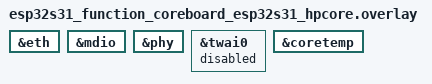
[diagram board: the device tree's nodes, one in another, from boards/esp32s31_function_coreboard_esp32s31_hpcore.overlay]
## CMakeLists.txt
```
# SPDX-License-Identifier: GPL-3.0-or-later

cmake_minimum_required(VERSION 3.20.0)

find_package(Zephyr REQUIRED HINTS $ENV{ZEPHYR_BASE})
project(esp_sdr_ptp_chain)

include(${CMAKE_CURRENT_LIST_DIR}/../../lib/esp_sdr/place.cmake)

target_sources(app PRIVATE src/main.c src/chain.c src/chain_math.c src/stats.c src/shell.c
  src/pps.c)
target_include_directories(app PRIVATE ${CMAKE_CURRENT_LIST_DIR}/../../include)
target_compile_options(app PRIVATE -O2)

# The hook's helpers in IRAM (the hook itself by place.h)
zephyr_linker_sources(RAMFUNC_SECTION ${CMAKE_CURRENT_LIST_DIR}/chain_ram.ld)
```

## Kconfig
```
# SPDX-License-Identifier: GPL-3.0-or-later

mainmenu "PTP chain"

config APP_CHAIN_RING
	int "Exchanges between the receive interrupt and the stats thread (a power of two)"
	range 16 4096
	default 512
	help
	  The thread drains the ring every few ms: it must hold the exchanges of the longest burst
	  (about one per frame) plus that. A full ring drops the exchange and counts it.

config APP_CHAIN_LOG
	int "Exchanges kept for chain dump (a power of two)"
	range 16 8192
	default 4096
	help
	  40 bytes each, in internal RAM.

config APP_CHAIN_PPS_PIN
	int "GPIO that carries the MAC's PPS output (J2 pin 7 is GPIO2)"
	range 0 28
	default 2
	help
	  GPIO0 to GPIO28 (gpio0 has 32 pins, 29 and up are reserved).

config APP_CHAIN_PTP_REF_HZ
	int "Reference clock of the MAC's PTP counter, Hz (PLL_F80M)"
	default 80000000

config APP_CHAIN_PPS
	bool "Route the PPS output to the pin"
	default y

config APP_CHAIN_THREAD_STACK
	int "Stack of the stats thread"
	default 3072

source "Kconfig.zephyr"
```

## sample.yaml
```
sample:
  name: PTP chain
  description: >-
    Clock offset between the DWMAC IEEE 1588 clocks of two ESP32-S31 CoreBoards on a direct
    Ethernet cable, from a ping-pong of raw frames stamped by the MAC hardware
common:
  tags: esp-sdr
  platform_allow:
    - esp32s31_function_coreboard/esp32s31/hpcore
  integration_platforms:
    - esp32s31_function_coreboard/esp32s31/hpcore
tests:
  sample.esp_sdr.ptp_chain:
    build_only: true
```

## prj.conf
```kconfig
# PTP chain: raw frames between two CoreBoards, stamped by the MAC. See README.rst.
CONFIG_ESP_SDR=y
CONFIG_ESP_SDR_PHY_ONLY=y

CONFIG_LOG=y
CONFIG_LOG_MODE_DEFERRED=y
CONFIG_LOG_BUFFER_SIZE=2048
CONFIG_MAIN_STACK_SIZE=2048
CONFIG_PRINTK=y
CONFIG_CBPRINTF_FP_SUPPORT=y
CONFIG_SHELL=y
CONFIG_SHELL_STACK_SIZE=4096
CONFIG_THREAD_NAME=y
# The stats thread fits lines in doubles
CONFIG_FPU_SHARING=y

# Ethernet only: the link comes up with the L2
CONFIG_NETWORKING=y
CONFIG_NET_L2_ETHERNET=y
CONFIG_ETH_DRIVER=y
# INF: the driver logs the PTP clock rate and sub-second increment at boot
CONFIG_ETHERNET_LOG_LEVEL_INF=y
CONFIG_PHY_LOG_LEVEL_WRN=y
CONFIG_MDIO_LOG_LEVEL_WRN=y
CONFIG_MDIO=y
# The stack needs one protocol (net_pkt.c); IPv4 without DHCP or addresses is idle
CONFIG_NET_IPV4=y
CONFIG_NET_IPV6=n
CONFIG_NET_BUF_DATA_SIZE=1536
CONFIG_NET_BUF_ALIGNMENT=64
CONFIG_NET_BUF_RX_COUNT=40
CONFIG_NET_PKT_RX_COUNT=16
CONFIG_NET_PKT_TX_COUNT=4
CONFIG_NET_BUF_TX_COUNT=4
CONFIG_DWMAC_NB_RX_DESCS=16
CONFIG_DWMAC_NB_TX_DESCS=16

# The MAC's hardware clock stamps every frame (a custom EtherType needs ALL). Digital rollover
# (the only mode): the sub-second field is in ns; chain_math.h also converts binary.
CONFIG_PTP_CLOCK=y
CONFIG_PTP_CLOCK_DWC_MAC_RX_TIMESTAMP_ALL=y
CONFIG_PTP_CLOCK_DWC_MAC_FINE_SSINC=y

CONFIG_ETH_DWMAC_RX_FAST=y
CONFIG_ETH_DWMAC_TX_FAST=y
CONFIG_ETH_DWMAC_TX_RAMFUNC=y
# Every frame is stamped: one completion interrupt each
CONFIG_ETH_DWMAC_TX_IRQ_EVERY=1

# Everything of the chain runs on CPU 0: the EMAC interrupt, the hook, the burst timer and the stats
# thread (pinned in src/stats.c). CPU 1 stays idle.
CONFIG_SMP=y
CONFIG_MP_MAX_NUM_CPUS=2
CONFIG_SCHED_CPU_MASK=y
CONFIG_SCHED_CPU_MASK_PIN_ONLY=y
CONFIG_IPI_OPTIMIZE=y

# Burst timer in 100 us ticks (the default interval is 7812 us)
CONFIG_SYS_CLOCK_TICKS_PER_SEC=10000

# Die temperature in the window lines (coretemp, enabled in the board overlay)
CONFIG_SENSOR=y
# Register peeks from the shell (devmem), for the PPS registers
CONFIG_DEVMEM_SHELL=y
```

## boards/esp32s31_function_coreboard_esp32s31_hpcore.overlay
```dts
/*
 * SPDX-License-Identifier: GPL-3.0-or-later
 *
 * The gigabit Ethernet of the ESP32-S31-Function-CoreBoard-1: YT8531 on RGMII (GPIO4-19, MDC 5,
 * MDIO 6, PHY reset 7). TWAI shares GPIO13/14 with TX_CLK and RX_CLK. GPIO2 (J2 pin 7) carries
 * the PPS output (CONFIG_APP_CHAIN_PPS_PIN).
 *
 * Clocks: the YT8531 runs from its own 25 MHz crystal (Y2); the MAC's PTP reference is PLL_F80M
 * (80 MHz), set up in code, not in this devicetree.
 */

&eth {
	status = "okay";
};

&mdio {
	status = "okay";
};

&phy {
	status = "okay";
	/* Gigabit: the 125 MHz reference clock, so let the PHY offer 1000BASE-T. */
	/delete-property/ default-speeds;
};

&twai0 {
	status = "disabled";
};

/* Die temperature for the window lines: the crystal's rate drifts with it */
&coretemp {
	status = "okay";
};
```

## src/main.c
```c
/*
 * SPDX-License-Identifier: GPL-3.0-or-later
 *
 * PTP chain: the offset between two DWMAC clocks from a ping-pong of raw frames. See ../README.rst.
 */
#include <zephyr/kernel.h>
#include <zephyr/logging/log.h>
#include <zephyr/net/ethernet.h>
#include <zephyr/net/net_if.h>

#include "chain.h"

LOG_MODULE_REGISTER(ptp_chain, LOG_LEVEL_INF);

int main(void)
{
	struct net_if *iface = net_if_get_first_by_type(&NET_L2_GET_NAME(ETHERNET));
	int ret;

	if (iface == NULL) {
		LOG_ERR("no Ethernet interface");
		return 0;
	}
	if (!net_if_is_up(iface)) {
		net_if_up(iface);
	}
	ret = chain_init(net_if_get_device(iface), iface);
	if (ret != 0) {
		LOG_ERR("rx hook: %d", ret);
		return 0;
	}
	chain_stats_init();
	if (IS_ENABLED(CONFIG_APP_CHAIN_PPS)) {
		ret = chain_pps_init();
		if (ret != 0) {
			LOG_ERR("pps: %d", ret);
		}
	}
	LOG_INF("ptp_chain ready: 'chain peer <mac>' and 'chain start' on one board");
	return 0;
}
```

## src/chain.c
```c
/*
 * SPDX-License-Identifier: GPL-3.0-or-later
 *
 * The chain of raw frames. The MAC driver calls chain_hook() in the EMAC interrupt for every
 * frame; ours (EtherType 0x88B5, magic) are answered at once from the hook, up to the hop count
 * the frame carries. The seme's burst timer starts each burst. Hook and timer both run on CPU 0
 * and neither nests in the other, so the state needs no lock: a guard flag only counts the case
 * where that assumption breaks.
 *
 * Frame, after the 14 byte Ethernet header, little endian, 40 bytes (padded to 60 on the wire):
 *   0 u16 magic 0x7c1a   2 u8 version 1   3 u8 flags
 *   4 u32 seq            8 u32 reply_to   12 u16 hops left   14 u16 0
 *  16 u32 rx_seq  20 u32 rx_sec  24 u32 rx_subsec   (sender's rx stamp of its last received frame)
 *  28 u32 tx_seq  32 u32 tx_sec  36 u32 tx_subsec   (sender's tx stamp of its previous frame)
 * flags: 0 reply (direct reply to reply_to), 1 sender is seme, 2 rx stamp valid, 3 tx stamp valid.
 * Each node numbers its own frames.
 */
#include <string.h>

#include <zephyr/kernel.h>
#include <zephyr/drivers/ethernet/eth_dwmac_fast.h>
#include <zephyr/net/net_if.h>
#include <zephyr/net_buf.h>
#include <zephyr/sys/atomic.h>
#include <zephyr/sys/util.h>

#include <esp_sdr/esp_sdr_place.h>

#include "chain.h"

#define ETYPE      0x88b5
#define HDR_LEN    14
#define MAGIC      0x7c1a
#define VERSION    1
#define FRAME_LEN  60
#define MAX_HOPS   1024
/* No new burst while a chain frame went in or out less than this ago */
#define QUIET_US   1000

#define P_MAGIC    0
#define P_VER      2
#define P_FLAGS    3
#define P_SEQ      4
#define P_REPLY_TO 8
#define P_HOPS     12
#define P_RX       16   /* seq, sec, subsec */
#define P_TX       28
#define P_END      40

#define F_REPLY    BIT(0)
#define F_SEME     BIT(1)
#define F_RX_OK    BIT(2)
#define F_TX_OK    BIT(3)

#define RING_SLOTS CONFIG_APP_CHAIN_RING
BUILD_ASSERT((RING_SLOTS & (RING_SLOTS - 1)) == 0, "CONFIG_APP_CHAIN_RING: a power of two");
BUILD_ASSERT(CONFIG_NET_BUF_RX_COUNT > CONFIG_DWMAC_NB_RX_DESCS, "receive buffers");

/*
 * Local always-inline accessors: the Zephyr ones (sys_get_le32, atomic_get) are static inline
 * functions that the compiler leaves as calls, to a copy in flash text.
 */
static __always_inline uint32_t get_le32(const uint8_t *p)
{
	return (uint32_t)p[0] | (uint32_t)p[1] << 8 | (uint32_t)p[2] << 16 | (uint32_t)p[3] << 24;
}

static __always_inline uint16_t get_le16(const uint8_t *p)
{
	return (uint16_t)(p[0] | p[1] << 8);
}

static __always_inline uint16_t get_be16(const uint8_t *p)
{
	return (uint16_t)(p[0] << 8 | p[1]);
}

static __always_inline void put_le32(uint32_t v, uint8_t *p)
{
	p[0] = (uint8_t)v;
	p[1] = (uint8_t)(v >> 8);
	p[2] = (uint8_t)(v >> 16);
	p[3] = (uint8_t)(v >> 24);
}

static __always_inline void put_le16(uint16_t v, uint8_t *p)
{
	p[0] = (uint8_t)v;
	p[1] = (uint8_t)(v >> 8);
}

static __always_inline void put_be16(uint16_t v, uint8_t *p)
{
	p[0] = (uint8_t)(v >> 8);
	p[1] = (uint8_t)v;
}

static __always_inline atomic_val_t aget(const atomic_t *a)
{
	return __atomic_load_n(a, __ATOMIC_ACQUIRE);
}

static __always_inline void aset(atomic_t *a, atomic_val_t v)
{
	__atomic_store_n(a, v, __ATOMIC_RELEASE);
}

enum { SLOT_FREE, SLOT_QUEUED, SLOT_DONE };

struct slot {
	uint8_t buf[FRAME_LEN] __aligned(4);
	struct dwmac_tx_stamp stamp;
	atomic_t state;
	uint32_t seq;
	bool harvested;
};

struct chain_counters chain_cnt;
const struct device *chain_eth;

static struct slot slots[CHAIN_TXN];
static struct chain_pair pair;
static uint32_t tx_seq;
static uint8_t own_mac[6];
static const uint8_t bcast_mac[6] = {0xff, 0xff, 0xff, 0xff, 0xff, 0xff};
/* Destination of our frames. peer_state: PEER_NONE, PEER_BUSY (bytes being written), PEER_KNOWN.
 * The bytes are written only in PEER_BUSY and published by the store of PEER_KNOWN.
 */
enum { PEER_NONE, PEER_BUSY, PEER_KNOWN };
static uint8_t peer_mac[6];
static atomic_t peer_state = PEER_NONE;
static atomic_t busy;
static uint32_t last_active_cyc;  /* k_cycle_get_32() at the last chain frame in or out */
static uint32_t quiet_cyc;       /* a burst starts only after this long without a chain frame */
static atomic_t role = CHAIN_IDLE;
static atomic_t rounds = 1;
static atomic_t interval_us = 7812;
static struct k_timer burst_timer;

static struct chain_xchg ring[RING_SLOTS];
static atomic_t ring_head, ring_tail;

static ESP_SDR_CODE(EVENT, chain_slot_done) void chain_slot_done(void *arg)
{
	struct slot *s = arg;

	aset(&s->state, SLOT_DONE);
}

/* Own frames the MAC has stamped since the last call: the stamps go to the pairing records. */
static ESP_SDR_CODE(EVENT, chain_harvest) void chain_harvest(void)
{
	for (unsigned int i = 0; i < CHAIN_TXN; i++) {
		struct slot *s = &slots[i];

		if (aget(&s->state) != SLOT_DONE || s->harvested) {
			continue;
		}
		s->harvested = true;
		if (s->stamp.valid) {
			struct chain_stamp st = {.sec = s->stamp.sec, .subsec = s->stamp.subsec,
						 .valid = true};

			chain_tx_stamp(&pair, s->seq, &st);
		} else {
			chain_cnt.tx_stamp_missing++;
		}
	}
}

static __always_inline void put_stamp(uint8_t *p, uint32_t seq, const struct chain_stamp *st)
{
	put_le32(seq, p);
	put_le32(st->sec, p + 4);
	put_le32(st->subsec, p + 8);
}

/* Queue the next own frame. It carries the rx stamp of the last received frame and the tx stamp of
 * the previous own frame.
 */
static ESP_SDR_CODE(EVENT, chain_send) bool chain_send(bool reply, uint32_t reply_to,
						       uint16_t hops)
{
	struct slot *s = &slots[tx_seq & (CHAIN_TXN - 1U)];
	struct dwmac_tx_frame f;
	struct chain_stamp pt;
	uint8_t *b = s->buf;
	uint8_t *p = b + HDR_LEN;
	uint8_t flags = 0;

	if (aget(&s->state) == SLOT_QUEUED) {
		chain_cnt.tx_busy++;
		return false;
	}
	if (aget(&peer_state) != PEER_KNOWN) {
		chain_cnt.tx_no_peer++;
		return false;
	}
	memset(b, 0, FRAME_LEN);
	memcpy(b, peer_mac, 6);
	if (aget(&peer_state) != PEER_KNOWN) {
		/* the thread changed the peer while we copied */
		chain_cnt.tx_no_peer++;
		return false;
	}
	memcpy(b + 6, own_mac, 6);
	put_be16(ETYPE, b + 12);
	put_le16(MAGIC, p + P_MAGIC);
	p[P_VER] = VERSION;
	if (reply) {
		flags |= F_REPLY;
	}
	if (aget(&role) == CHAIN_SEME) {
		flags |= F_SEME;
	}
	put_le32(tx_seq, p + P_SEQ);
	put_le32(reply_to, p + P_REPLY_TO);
	put_le16(hops, p + P_HOPS);
	if (pair.last.valid && pair.last.rx.valid) {
		put_stamp(p + P_RX, pair.last.seq, &pair.last.rx);
		flags |= F_RX_OK;
	}
	if (chain_tx_get(&pair, tx_seq - 1U, &pt)) {
		put_stamp(p + P_TX, tx_seq - 1U, &pt);
		flags |= F_TX_OK;
	}
	p[P_FLAGS] = flags;

	s->stamp.valid = false;
	s->seq = tx_seq;
	s->harvested = false;
	aset(&s->state, SLOT_QUEUED);
	chain_tx_register(&pair, tx_seq, reply_to, reply);
	f = (struct dwmac_tx_frame){.b1 = b, .l1 = FRAME_LEN, .b2 = NULL, .l2 = 0,
				    .done = chain_slot_done, .arg = s, .stamp = &s->stamp};
	if (dwmac_send_frames(chain_eth, &f, 1) != 1) {
		aset(&s->state, SLOT_FREE);
		chain_cnt.tx_fail++;
		return false;
	}
	tx_seq++;
	chain_cnt.tx_sent++;
	last_active_cyc = k_cycle_get_32();
	return true;
}

static __always_inline void ring_push(const struct chain_xchg *x)
{
	uint32_t h = (uint32_t)aget(&ring_head);

	if (h - (uint32_t)aget(&ring_tail) >= RING_SLOTS) {
		chain_cnt.ring_overflow++;
		return;
	}
	ring[h & (RING_SLOTS - 1U)] = *x;
	aset(&ring_head, (atomic_val_t)(h + 1U));
}

bool chain_ring_pop(struct chain_xchg *x)
{
	uint32_t t = (uint32_t)aget(&ring_tail);

	if (t == (uint32_t)aget(&ring_head)) {
		return false;
	}
	*x = ring[t & (RING_SLOTS - 1U)];
	aset(&ring_tail, (atomic_val_t)(t + 1U));
	return true;
}

static __always_inline void get_stamp(const uint8_t *p, uint32_t *seq, struct chain_stamp *st, bool ok)
{
	*seq = get_le32(p);
	st->sec = get_le32(p + 4);
	st->subsec = get_le32(p + 8);
	st->valid = ok;
}

static ESP_SDR_CODE(EVENT, chain_hook) bool chain_hook(const struct device *dev,
						       const struct dwmac_rx_frame *f, void *user)
{
	const uint8_t *p;
	struct chain_rx_in in;
	struct chain_rx_res res;
	uint8_t flags;
	uint16_t hops;

	ARG_UNUSED(dev);
	ARG_UNUSED(user);
	if (f->len < HDR_LEN + P_END || get_be16(f->data + 12) != ETYPE) {
		return false;
	}
	p = f->data + HDR_LEN;
	if (get_le16(p + P_MAGIC) != MAGIC || p[P_VER] != VERSION ||
	    memcmp(f->data + 6, own_mac, 6) == 0) {
		return false;
	}
	/* for us or broadcast (an older image still sends those) */
	if (memcmp(f->data, own_mac, 6) != 0 && memcmp(f->data, bcast_mac, 6) != 0) {
		return false;
	}
	/* the uke learns the peer from the first valid frame, and keeps it */
	if (atomic_cas(&peer_state, PEER_NONE, PEER_BUSY)) {
		memcpy(peer_mac, f->data + 6, 6);
		aset(&peer_state, PEER_KNOWN);
	}
	if (!atomic_cas(&busy, 0, 1)) {
		chain_cnt.reentry++;
		return false;
	}
	chain_harvest();
	flags = p[P_FLAGS];
	in.seq = get_le32(p + P_SEQ);
	in.is_reply = (flags & F_REPLY) != 0;
	in.reply_to = get_le32(p + P_REPLY_TO);
	get_stamp(p + P_RX, &in.rx_seq, &in.rx, (flags & F_RX_OK) != 0);
	get_stamp(p + P_TX, &in.tx_seq, &in.tx, (flags & F_TX_OK) != 0);
	in.local_rx = (struct chain_stamp){.sec = f->timestamp_sec, .subsec = f->timestamp_subsec,
					   .valid = f->timestamp_valid};
	hops = get_le16(p + P_HOPS);

	if ((flags & F_SEME) != 0) {
		/* two semes: the lower MAC stays */
		if (aget(&role) == CHAIN_SEME && memcmp(f->data + 6, own_mac, 6) < 0) {
			k_timer_stop(&burst_timer);
			aset(&role, CHAIN_UKE);
		} else if (aget(&role) == CHAIN_IDLE) {
			aset(&role, CHAIN_UKE);
		}
	}
	chain_cnt.rx_chain++;
	last_active_cyc = k_cycle_get_32();
	if (!f->timestamp_valid) {
		chain_cnt.rx_nostamp++;
	}
	chain_rx(&pair, &in, &res);
	chain_cnt.rx_lost += res.lost;
	if (res.stale) {
		chain_cnt.rx_stale++;
	} else {
		for (unsigned int i = 0; i < res.n; i++) {
			ring_push(&res.x[i]);
		}
		chain_cnt.exchanges += res.n;
		if (hops > 0) {
			chain_send(true, in.seq, (hops > MAX_HOPS ? MAX_HOPS : hops) - 1U);
		} else {
			chain_cnt.chain_end++;
		}
	}
	aset(&busy, 0);
	net_buf_unref(f->buf);
	return true;
}

/* Tick of the seme: the first frame of a burst. */
static ESP_SDR_CODE(EVENT, chain_burst) void chain_burst(struct k_timer *t)
{
	ARG_UNUSED(t);
	if (!atomic_cas(&busy, 0, 1)) {
		chain_cnt.reentry++;
		return;
	}
	if (k_cycle_get_32() - last_active_cyc < quiet_cyc) {
		chain_cnt.burst_skipped++;
		aset(&busy, 0);
		return;
	}
	chain_harvest();
	if (chain_send(false, 0, 2U * (uint32_t)aget(&rounds) - 1U)) {
		chain_cnt.bursts++;
	}
	aset(&busy, 0);
}

int chain_init(const struct device *eth, struct net_if *iface)
{
	chain_eth = eth;
	memcpy(own_mac, net_if_get_link_addr(iface)->addr, 6);
	chain_pair_init(&pair, CHAIN_DIGITAL);
	quiet_cyc = k_us_to_cyc_ceil32(QUIET_US);
	k_timer_init(&burst_timer, chain_burst, NULL);
	return dwmac_rx_hook_set(eth, chain_hook, NULL, NULL);
}

int chain_start(uint32_t us, uint32_t r)
{
	if (aget(&peer_state) != PEER_KNOWN) {
		return -ENOTCONN;
	}
	if (us != 0) {
		atomic_set(&interval_us, (atomic_val_t)us);
	}
	if (r != 0) {
		atomic_set(&rounds, (atomic_val_t)r);
	}
	atomic_set(&role, CHAIN_SEME);
	k_timer_start(&burst_timer, K_USEC((uint32_t)atomic_get(&interval_us)),
		      K_USEC((uint32_t)atomic_get(&interval_us)));
	return 0;
}

/* Take the peer for writing. The hook (ISR) never waits: it only tries PEER_NONE -> PEER_BUSY. */
static void peer_take(void)
{
	atomic_val_t old;

	do {
		old = aget(&peer_state);
	} while (old == PEER_BUSY || !atomic_cas(&peer_state, old, PEER_BUSY));
}

int chain_peer_set(const uint8_t mac[6])
{
	if (aget(&role) != CHAIN_IDLE) {
		return -EBUSY;
	}
	peer_take();
	memcpy(peer_mac, mac, 6);
	aset(&peer_state, PEER_KNOWN);
	return 0;
}

int chain_peer_clear(void)
{
	if (aget(&role) != CHAIN_IDLE) {
		return -EBUSY;
	}
	peer_take();
	aset(&peer_state, PEER_NONE);
	return 0;
}

bool chain_peer_get(uint8_t mac[6])
{
	if (aget(&peer_state) != PEER_KNOWN) {
		return false;
	}
	memcpy(mac, peer_mac, 6);
	return aget(&peer_state) == PEER_KNOWN;
}

void chain_stop(void)
{
	k_timer_stop(&burst_timer);
	atomic_set(&role, CHAIN_IDLE);
}

enum chain_role chain_role_get(void)
{
	return (enum chain_role)atomic_get(&role);
}

const uint8_t *chain_mac(void)
{
	return own_mac;
}

uint32_t chain_interval_us(void)
{
	return (uint32_t)atomic_get(&interval_us);
}

uint32_t chain_rounds(void)
{
	return (uint32_t)atomic_get(&rounds);
}
```

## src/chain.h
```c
/*
 * SPDX-License-Identifier: GPL-3.0-or-later
 *
 * The chain: hook, sender, burst timer, counters, the exchange ring. See ../README.rst.
 */
#ifndef CHAIN_H_
#define CHAIN_H_

#include <stdbool.h>
#include <stdint.h>

#include <zephyr/device.h>
#include <zephyr/net/net_if.h>

#include "chain_math.h"

#define CHAIN_DIGITAL IS_ENABLED(CONFIG_PTP_CLOCK_DWC_MAC_DIGITAL_ROLLOVER)

enum chain_role {
	CHAIN_IDLE,  /* answers, never starts */
	CHAIN_SEME,  /* starts bursts */
	CHAIN_UKE,   /* has seen a seme */
};

/* Written by the interrupt and the burst timer (CPU 0), read by the thread: only ever counting up */
struct chain_counters {
	uint32_t tx_sent;
	uint32_t tx_busy;           /* slot still queued: ring overflow, frame not sent */
	uint32_t tx_no_peer;        /* no peer MAC known: frame not sent */
	uint32_t tx_fail;           /* the driver took no frame */
	uint32_t tx_stamp_missing;
	uint32_t rx_chain;
	uint32_t rx_nostamp;
	uint32_t rx_stale;
	uint32_t rx_lost;           /* peer frames missing by sequence gap */
	uint32_t exchanges;
	uint32_t ring_overflow;     /* exchange ring full */
	uint32_t reentry;
	uint32_t bursts;
	uint32_t chain_end;         /* bursts that ended here (hop count 0) */
	uint32_t burst_skipped;     /* timer ticks skipped: the previous burst was still running */
	uint32_t rejected;          /* exchanges with an implausible delay (stats thread) */
};

extern struct chain_counters chain_cnt;
extern const struct device *chain_eth;

int chain_init(const struct device *eth, struct net_if *iface);
/** Start bursts. Returns 0, or -ENOTCONN when no peer MAC is known (chain_peer_set() first). */
int chain_start(uint32_t interval_us, uint32_t rounds);
/** Peer MAC (destination of our frames), learned from the first chain frame or set by the user.
 *  Set and clear return -EBUSY unless the role is CHAIN_IDLE.
 */
int chain_peer_set(const uint8_t mac[6]);
int chain_peer_clear(void);
bool chain_peer_get(uint8_t mac[6]);
void chain_stop(void);
enum chain_role chain_role_get(void);
const uint8_t *chain_mac(void);
uint32_t chain_interval_us(void);
uint32_t chain_rounds(void);

/** Next exchange of the ring (thread side). */
bool chain_ring_pop(struct chain_xchg *x);

/* stats.c */
void chain_stats_init(void);
extern atomic_t chain_stat_on;
extern atomic_t chain_servo_on;
uint32_t chain_log_count(void);
bool chain_log_get(uint32_t idx, struct chain_xchg *x);
uint32_t chain_servo_steps(void);
/** Settings of the next 'servo on': period, loop bandwidth in mHz, step clamp in ns. */
void chain_servo_config(uint32_t period_ms, uint32_t bw_mhz, uint32_t clamp_ns);

/* The log entry that marks a servo step: t_ps[0] the step in ps */
#define CHAIN_LOG_STEP 0xffffffffU

/* pps.c */
int chain_pps_init(void);
int chain_pps_set(uint32_t n);
/** Flexible mode: a pulse of width_us every second, rising at a PTP second boundary. */
struct chain_pps_info {
	uint32_t tick_ps;        /* the unit of interval and width */
	uint32_t interval_ticks;
	uint32_t width_ticks;
	uint64_t start_sec;      /* the PTP second the first pulse rises at */
};

int chain_pps_flex(uint32_t width_us, bool ref_clk, struct chain_pps_info *info);
int chain_pps_flex_stop(void);

#endif /* CHAIN_H_ */
```

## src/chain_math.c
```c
/*
 * SPDX-License-Identifier: GPL-3.0-or-later
 *
 * See chain_math.h. chain_rx and the tx records run in the receive interrupt: chain_ram.ld puts
 * them in IRAM.
 */
#include <math.h>
#include <string.h>

#include "chain_math.h"

void chain_pair_init(struct chain_pair *p, bool digital)
{
	memset(p, 0, sizeof(*p));
	p->digital = digital;
}

static struct chain_txrec *tx_find(struct chain_pair *p, uint32_t seq)
{
	struct chain_txrec *r = &p->tx[seq & (CHAIN_TXN - 1U)];

	return (r->used && r->seq == seq) ? r : NULL;
}

void chain_tx_register(struct chain_pair *p, uint32_t seq, uint32_t reply_to, bool is_reply)
{
	struct chain_txrec *r = &p->tx[seq & (CHAIN_TXN - 1U)];

	r->used = true;
	r->seq = seq;
	r->reply_to = reply_to;
	r->is_reply = is_reply;
	r->stamp.valid = false;
}

void chain_tx_stamp(struct chain_pair *p, uint32_t seq, const struct chain_stamp *s)
{
	struct chain_txrec *r = tx_find(p, seq);

	if (r != NULL) {
		r->stamp = *s;
	}
}

bool chain_tx_get(const struct chain_pair *p, uint32_t seq, struct chain_stamp *s)
{
	const struct chain_txrec *r = &p->tx[seq & (CHAIN_TXN - 1U)];

	if (!r->used || r->seq != seq || !r->stamp.valid) {
		return false;
	}
	*s = r->stamp;
	return true;
}

static void emit(const struct chain_pair *p, struct chain_rx_res *res, uint32_t seq,
		 const struct chain_stamp *t1, const struct chain_stamp *t2,
		 const struct chain_stamp *t3, const struct chain_stamp *t4)
{
	struct chain_xchg *x = &res->x[res->n++];

	x->seq = seq;
	x->base_sec = t1->sec;
	x->t_ps[0] = chain_stamp_rel_ps(t1, t1->sec, p->digital);
	x->t_ps[1] = chain_stamp_rel_ps(t2, t1->sec, p->digital);
	x->t_ps[2] = chain_stamp_rel_ps(t3, t1->sec, p->digital);
	x->t_ps[3] = chain_stamp_rel_ps(t4, t1->sec, p->digital);
}

void chain_rx(struct chain_pair *p, const struct chain_rx_in *in, struct chain_rx_res *res)
{
	struct chain_rxrec *l = &p->last;
	struct chain_txrec *m;

	res->n = 0;
	res->stale = false;
	res->lost = 0;

	if (l->valid) {
		int32_t d = (int32_t)(in->seq - l->seq);

		if (d <= 0 && d >= -CHAIN_STALE_WIN) {
			res->stale = true;
			return;
		}
		if (d > 0 && (uint32_t)d < CHAIN_RESYNC) {
			res->lost = (uint32_t)d - 1U;
		}
	}

	/*
	 * Pair started by us: own m, peer's direct reply l (carries its rx of m), and now the frame
	 * after l carries the peer's tx stamp of l.
	 */
	if (l->valid && l->is_reply && l->rx.valid && l->crx.valid && in->tx.valid &&
	    in->tx_seq == l->seq && l->crx_seq == l->reply_to) {
		m = tx_find(p, l->reply_to);
		if (m != NULL && m->stamp.valid) {
			emit(p, res, m->seq, &m->stamp, &l->crx, &in->tx, &l->rx);
		}
	}

	/*
	 * Pair started by the peer: its frame l (rx here) and our direct reply m. Any later frame of
	 * the peer (a reply to m or the first frame of the next burst) is the carrier: it holds the
	 * peer's tx stamp of l (tx_seq) and its rx stamp of m (rx_seq).
	 */
	if (l->valid && l->rx.valid && in->tx.valid && in->rx.valid && in->tx_seq == l->seq) {
		m = tx_find(p, in->rx_seq);
		if (m != NULL && m->is_reply && m->reply_to == l->seq && m->stamp.valid) {
			emit(p, res, l->seq, &m->stamp, &in->rx, &in->tx, &l->rx);
		}
	}

	l->valid = true;
	l->seq = in->seq;
	l->is_reply = in->is_reply;
	l->reply_to = in->reply_to;
	l->rx = in->local_rx;
	l->crx_seq = in->rx_seq;
	l->crx = in->rx;
}

void chain_fit_reset(struct chain_fit *f)
{
	memset(f, 0, sizeof(*f));
}

void chain_fit_add(struct chain_fit *f, int64_t x_ps, int64_t y_ps)
{
	double dx_ps, dy_ps;

	if (f->n == 0) {
		f->x0_ps = (double)x_ps;
		f->y0_ps = (double)y_ps;
	}
	dx_ps = (double)x_ps - f->x0_ps;
	dy_ps = (double)y_ps - f->y0_ps;
	f->n++;
	f->sx_ps += dx_ps;
	f->sy_ps += dy_ps;
	f->sxx_ps2 += dx_ps * dx_ps;
	f->sxy_ps2 += dx_ps * dy_ps;
	f->syy_ps2 += dy_ps * dy_ps;
}

int chain_fit_end(const struct chain_fit *f, struct chain_fit_res *r)
{
	double n = (double)f->n;
	double cxx_ps2, cxy_ps2, cyy_ps2, slope, var;

	memset(r, 0, sizeof(*r));
	r->n = f->n;
	if (f->n == 0) {
		return -1;
	}
	r->x_mean_ps = f->x0_ps + f->sx_ps / n;
	r->y_mean_ps = f->y0_ps + f->sy_ps / n;
	cxx_ps2 = f->sxx_ps2 - f->sx_ps * f->sx_ps / n;
	cxy_ps2 = f->sxy_ps2 - f->sx_ps * f->sy_ps / n;
	cyy_ps2 = f->syy_ps2 - f->sy_ps * f->sy_ps / n;
	if (f->n < 2 || cxx_ps2 <= 0.0) {
		r->rms_ps = sqrt(cyy_ps2 > 0.0 ? cyy_ps2 / n : 0.0);
		return -1;
	}
	slope = cxy_ps2 / cxx_ps2;
	var = (cyy_ps2 - slope * cxy_ps2) / n;
	r->rate_ppb = slope * 1e9;
	r->rms_ps = sqrt(var > 0.0 ? var : 0.0);
	return 0;
}

void chain_servo_init(struct chain_servo *s, double period_s, double bw_hz, double clamp_ps)
{
	double wn = CHAIN_TAU * bw_hz;

	memset(s, 0, sizeof(*s));
	s->kp = 2.0 * wn / 1e3;
	s->ki = wn * wn / 1e3;
	s->period_s = period_s;
	s->clamp_ps = clamp_ps;
}

double chain_servo_update(struct chain_servo *s, double offset_ps, int64_t *step_ps)
{
	double integ, out;

	*step_ps = 0;
	if (fabs(offset_ps) > s->clamp_ps) {
		*step_ps = (int64_t)llround(offset_ps);
		s->steps++;
		return s->rate_ppb;
	}
	integ = s->integ_ppb + s->ki * offset_ps * s->period_s;
	out = s->kp * offset_ps + integ;
	/* the output limit also stops the integrator (no windup against it) */
	if (out > CHAIN_SERVO_MAX_PPB) {
		integ -= out - CHAIN_SERVO_MAX_PPB;
		out = CHAIN_SERVO_MAX_PPB;
	} else if (out < -CHAIN_SERVO_MAX_PPB) {
		integ -= out + CHAIN_SERVO_MAX_PPB;
		out = -CHAIN_SERVO_MAX_PPB;
	}
	s->integ_ppb = integ;
	s->rate_ppb = out;
	return out;
}
```

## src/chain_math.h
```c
/*
 * SPDX-License-Identifier: GPL-3.0-or-later
 *
 * The arithmetic of the PTP chain: MAC stamps to picoseconds, the pairing of frames into
 * exchanges, offset and delay of an exchange, the least-squares line. Only stdint, stdbool and
 * math: the host unit test (tests/unit/ptp_chain) compiles chain_math.c as it is.
 *
 * Time is int64 picoseconds. A stamp is (sec, subsec) from the MAC; seconds are taken relative to
 * a base second (the one of t1), so a clock that is off by up to CHAIN_SEC_LIM seconds (97 days)
 * still fits; beyond that the difference saturates.
 */
#ifndef CHAIN_MATH_H_
#define CHAIN_MATH_H_

#include <stdbool.h>
#include <stdint.h>

/* The hot helpers are part of the caller: it runs from IRAM */
#define CHAIN_INLINE static inline __attribute__((always_inline))

#define CHAIN_PS_PER_SEC 1000000000000LL
#define CHAIN_SEC_LIM    8000000

/* 1e12 = 2^12 * 5^12: a binary sub-second (units of 2^-31 s) is subsec * 5^12 / 2^19 ps, exact */
#define CHAIN_BIN_MUL    244140625ULL
#define CHAIN_BIN_SHIFT  19
#define CHAIN_BIN_MASK   0x7fffffffU
#define CHAIN_NS_PER_SEC 1000000000U

/* Own frames kept for pairing (a power of two); the chain needs two */
#define CHAIN_TXN        8U
/* A frame this far behind the last one is stale (reordered or repeated), further is a peer restart */
#define CHAIN_STALE_WIN  64
/* A jump of this many frames or more is a restart of the peer, not a loss */
#define CHAIN_RESYNC     65536U

struct chain_stamp {
	uint32_t sec;
	uint32_t subsec;
	bool valid;
};

/** a is older than b, u32 sequence numbers with wrap */
CHAIN_INLINE bool chain_seq_lt(uint32_t a, uint32_t b)
{
	return (int32_t)(a - b) < 0;
}

/** Sub-second field to ps: digital rollover counts ns, binary counts 2^-31 s. */
CHAIN_INLINE int64_t chain_subsec_to_ps(uint32_t subsec, bool digital)
{
	if (digital) {
		if (subsec >= CHAIN_NS_PER_SEC) {
			subsec = CHAIN_NS_PER_SEC - 1U;
		}
		return (int64_t)subsec * 1000;
	}
	return (int64_t)(((uint64_t)(subsec & CHAIN_BIN_MASK) * CHAIN_BIN_MUL) >> CHAIN_BIN_SHIFT);
}

/** Stamp in ps counted from the start of second base_sec (negative before it; seconds saturate). */
CHAIN_INLINE int64_t chain_stamp_rel_ps(const struct chain_stamp *s, uint32_t base_sec,
					 bool digital)
{
	int32_t ds = (int32_t)(s->sec - base_sec);

	if (ds > CHAIN_SEC_LIM) {
		ds = CHAIN_SEC_LIM;
	} else if (ds < -CHAIN_SEC_LIM) {
		ds = -CHAIN_SEC_LIM;
	}
	return (int64_t)ds * CHAIN_PS_PER_SEC + chain_subsec_to_ps(s->subsec, digital);
}

/*
 * An exchange as seen from the local node X, the peer being Y:
 * t1 = X tx, t2 = Y rx, t3 = Y tx, t4 = X rx (all relative to base_sec).
 * A pair started by X is natural order. A pair started by Y (Y tx p, X rx p, X tx s, Y rx s) is
 * stored as t1 = X tx s, t2 = Y rx s, t3 = Y tx p, t4 = X rx p: the same formulas give Y minus X.
 */
struct chain_xchg {
	uint32_t seq;      /* first frame of the pair */
	uint32_t base_sec;
	int64_t t_ps[4];
};

/** Y minus X, ps (floor of half ps) */
CHAIN_INLINE int64_t chain_xchg_offset_ps(const struct chain_xchg *x)
{
	return ((x->t_ps[1] - x->t_ps[0]) - (x->t_ps[3] - x->t_ps[2])) >> 1;
}

/** Mean of the two one-way delays, ps */
CHAIN_INLINE int64_t chain_xchg_delay_ps(const struct chain_xchg *x)
{
	return ((x->t_ps[1] - x->t_ps[0]) + (x->t_ps[3] - x->t_ps[2])) >> 1;
}

/* Pairing */

struct chain_txrec {
	bool used;
	bool is_reply;
	uint32_t seq;
	uint32_t reply_to;
	struct chain_stamp stamp;
};

struct chain_rxrec {
	bool valid;
	bool is_reply;
	uint32_t seq;
	uint32_t reply_to;
	struct chain_stamp rx;  /* local rx stamp of this frame */
	uint32_t crx_seq;       /* the stamp the peer carried: its rx of frame crx_seq */
	struct chain_stamp crx;
};

struct chain_pair {
	bool digital;
	struct chain_txrec tx[CHAIN_TXN];
	struct chain_rxrec last;
};

/** A received chain frame: its header, the stamps it carries, and the local rx stamp. */
struct chain_rx_in {
	uint32_t seq;
	bool is_reply;
	uint32_t reply_to;
	uint32_t rx_seq;
	struct chain_stamp rx;  /* peer's rx stamp of its last received frame rx_seq */
	uint32_t tx_seq;
	struct chain_stamp tx;  /* peer's tx stamp of its previous frame tx_seq */
	struct chain_stamp local_rx;
};

struct chain_rx_res {
	uint8_t n;              /* exchanges completed by this frame (0 to 2) */
	bool stale;             /* repeated or reordered: ignored */
	uint32_t lost;          /* peer frames missing since the last one */
	struct chain_xchg x[2];
};

void chain_pair_init(struct chain_pair *p, bool digital);
/** Own frame seq is queued (reply_to meaningful if is_reply). */
void chain_tx_register(struct chain_pair *p, uint32_t seq, uint32_t reply_to, bool is_reply);
/** The MAC's tx stamp of own frame seq arrived. */
void chain_tx_stamp(struct chain_pair *p, uint32_t seq, const struct chain_stamp *s);
/** The tx stamp of own frame seq, false if unknown or the stamp is invalid. */
bool chain_tx_get(const struct chain_pair *p, uint32_t seq, struct chain_stamp *s);
/** Process a received frame: completes the exchanges it allows, then becomes the last frame. */
void chain_rx(struct chain_pair *p, const struct chain_rx_in *in, struct chain_rx_res *res);

/* Least squares line y = y_mean + slope (x - x_mean), accumulated sample by sample */

struct chain_fit {
	uint32_t n;
	double x0_ps, y0_ps;                 /* first sample: the sums are about it */
	double sx_ps, sy_ps;
	double sxx_ps2, sxy_ps2, syy_ps2;
};

struct chain_fit_res {
	uint32_t n;
	double x_mean_ps;
	double y_mean_ps;    /* the line at x_mean_ps */
	double rate_ppb;     /* slope of y over x */
	double rms_ps;       /* residual */
};

void chain_fit_reset(struct chain_fit *f);
void chain_fit_add(struct chain_fit *f, int64_t x_ps, int64_t y_ps);
/** 0 if the line is defined; -1 (means filled, rate 0) for fewer than 2 points or equal x. */
int chain_fit_end(const struct chain_fit *f, struct chain_fit_res *r);

/*
 * Rate-only PI servo of the uke. Input: offset of the seme (peer minus local, ps), the mean over
 * one update period. Output: the absolute rate of the local clock in ppb of nominal (ratio
 * 1 + rate_ppb * 1e-9). Positive offset means the local clock is behind: speed up.
 *
 * Plant: offset' = -1e3 (rate_ppb + clock error) ps/s. With rate = kp e + integ and
 * integ' = ki e this is a second order loop of natural frequency wn = TAU bw_hz,
 * critically damped: kp = 2 wn / 1e3, ki = wn^2 / 1e3 (ppb per ps, ppb per ps and s).
 * A step (|offset| above the clamp) is returned to the caller and the update leaves rate and
 * integrator alone: the learned rate survives a step and nothing winds up.
 */
#define CHAIN_TAU 6.283185307179586
#define CHAIN_SERVO_MAX_PPB 100000.0

struct chain_servo {
	double kp;          /* ppb per ps */
	double ki;          /* ppb per ps and s */
	double period_s;
	double clamp_ps;    /* above this the clock is stepped */
	double integ_ppb;
	double rate_ppb;    /* last output */
	uint32_t steps;
};

void chain_servo_init(struct chain_servo *s, double period_s, double bw_hz, double clamp_ps);
/** One update; *step_ps is the step to apply to the local clock (0: none). Returns rate_ppb. */
double chain_servo_update(struct chain_servo *s, double offset_ps, int64_t *step_ps);

#endif /* CHAIN_MATH_H_ */
```

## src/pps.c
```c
/*
 * SPDX-License-Identifier: GPL-3.0-or-later
 *
 * The MAC's PPS0 output on a GPIO: the pad is made an output by the GPIO driver, then the GPIO
 * matrix connects the EMAC PPS signal to it. The pulse shape is unverified (README).
 */
#include <zephyr/device.h>
#include <zephyr/devicetree.h>
#include <zephyr/drivers/gpio.h>
#include <zephyr/drivers/ptp_clock.h>
#include <zephyr/net/ptp_time.h>
#include <zephyr/sys/util.h>

#include <esp_rom_gpio.h>
#include <soc/emac_ptp_struct.h>
#include <soc/gpio_sig_map.h>

#include "chain.h"

int chain_pps_init(void)
{
	const struct device *gpio = DEVICE_DT_GET(DT_NODELABEL(gpio0));
	int ret;

	if (!device_is_ready(gpio)) {
		return -ENODEV;
	}
	ret = gpio_pin_configure(gpio, CONFIG_APP_CHAIN_PPS_PIN, GPIO_OUTPUT_INACTIVE);
	if (ret != 0) {
		return ret;
	}
	esp_rom_gpio_connect_out_signal(CONFIG_APP_CHAIN_PPS_PIN, EMAC_PTP_PPS_PAD_OUT_IDX, false, false);
	return 0;
}

/* PPS control register (EMAC_PTP + 0x2c, the DWMAC 3.7 PPSCTRL at 0x72c) */
#define PPS_CTRL_PPSEN0        BIT(4)      /* flexible mode: PPSCMD0 is a command */
#define PPS_CTRL_TRGT_SHIFT    5           /* TRGTMODSEL0, 2 bits */
#define PPS_TRGT_PPS_ONLY      3U          /* target time starts or stops the output, no interrupt */
#define PPS_CMD_START_TRAIN    2U
#define PPS_CMD_STOP_NOW       5U
/* The registers are 31 bits of nanoseconds and a busy flag */
#define PPS_WAIT_LOOPS         100000

/** Fixed mode: PPS0 control field (4 bits), PPSEN0 off. */
int chain_pps_set(uint32_t n)
{
	if (n > 15U) {
		return -EINVAL;
	}
	EMAC_PTP.pps_ctrl.val = n;
	return 0;
}

static int target_wait(volatile uint32_t *nsec_reg)
{
	for (int i = 0; i < PPS_WAIT_LOOPS; i++) {
		if ((*nsec_reg & BIT(31)) == 0U) {
			return 0;
		}
	}
	return -ETIMEDOUT;
}

/*
 * Is flexible mode there: select it (PPSEN0, stop command) and write a pattern to the PPS0
 * interval register. The S31 keeps only the fixed-mode field (pps_ctrl reads back 0x5) and the
 * interval reads 0: then the old control value is written back, so a fixed-mode output runs on.
 */
static int flex_probe(void)
{
	uint32_t ctrl_old = EMAC_PTP.pps_ctrl.val;

	EMAC_PTP.pps_ctrl.val = PPS_CTRL_PPSEN0 | (PPS_TRGT_PPS_ONLY << PPS_CTRL_TRGT_SHIFT) |
				PPS_CMD_STOP_NOW;
	EMAC_PTP.pps0_interval.val = 0x5a5aa5a5U;
	if ((EMAC_PTP.pps_ctrl.val & PPS_CTRL_PPSEN0) == 0U ||
	    EMAC_PTP.pps0_interval.val != 0x5a5aa5a5U) {
		EMAC_PTP.pps_ctrl.val = ctrl_old;
		return -ENODEV;
	}
	return 0;
}

/*
 * Flexible mode: a pulse train, interval 1 s, width width_us, first rising edge at the PTP second
 * two seconds on (the next full second plus one, so the registers are in before it). Interval and
 * width are programmed as ticks - 1. A tick is the sub-second increment of the PTP clock
 * (SSIR: 13 ns with FINE_SSINC at 80 MHz), or with ref_clk one cycle of the PTP reference clock
 * (12.5 ns): which unit the MAC counts in is unverified, read it off the scope.
 */
int chain_pps_flex(uint32_t width_us, bool ref_clk, struct chain_pps_info *info)
{
	const struct device *clk = DEVICE_DT_GET(DT_NODELABEL(ptp_clock));
	struct net_ptp_time t;
	uint64_t tick_ps;
	int ret;

	if (width_us == 0U) {
		width_us = 1000U;
	}
	if (ref_clk) {
		tick_ps = (uint64_t)CHAIN_PS_PER_SEC / CONFIG_APP_CHAIN_PTP_REF_HZ;
	} else {
		tick_ps = (uint64_t)chain_subsec_to_ps(EMAC_PTP.sub_sec_incre.sub_second_incre_value,
						      CHAIN_DIGITAL);
	}
	if (tick_ps == 0U) {
		return -EINVAL;
	}
	info->tick_ps = (uint32_t)tick_ps;
	info->interval_ticks = (uint32_t)(((uint64_t)CHAIN_PS_PER_SEC + tick_ps / 2U) / tick_ps);
	info->width_ticks = (uint32_t)(((uint64_t)width_us * 1000000U + tick_ps / 2U) / tick_ps);
	if (info->width_ticks == 0U || info->width_ticks >= info->interval_ticks) {
		return -EINVAL;
	}
	ret = flex_probe();
	if (ret != 0) {
		return ret;
	}
	ret = ptp_clock_get(clk, &t);
	if (ret != 0) {
		return ret;
	}
	info->start_sec = t.second + 2U;

	/* stop what runs, select flexible mode, program, then the start command */
	EMAC_PTP.pps_ctrl.val = PPS_CTRL_PPSEN0 | (PPS_TRGT_PPS_ONLY << PPS_CTRL_TRGT_SHIFT) |
				PPS_CMD_STOP_NOW;
	EMAC_PTP.pps_ctrl.val = PPS_CTRL_PPSEN0 | (PPS_TRGT_PPS_ONLY << PPS_CTRL_TRGT_SHIFT);
	EMAC_PTP.pps0_interval.val = info->interval_ticks - 1U;
	EMAC_PTP.pps0_width.val = info->width_ticks - 1U;
	EMAC_PTP.tgt_seconds.val = (uint32_t)info->start_sec;
	ret = target_wait(&EMAC_PTP.tgt_nanosec.val);
	if (ret != 0) {
		return ret;
	}
	EMAC_PTP.tgt_nanosec.val = 0U;
	ret = target_wait(&EMAC_PTP.tgt_nanosec.val);
	if (ret != 0) {
		return ret;
	}
	EMAC_PTP.pps_ctrl.val = PPS_CTRL_PPSEN0 | (PPS_TRGT_PPS_ONLY << PPS_CTRL_TRGT_SHIFT) |
				PPS_CMD_START_TRAIN;
	return 0;
}

/* Stops a flexible train; -ENODEV and nothing changed without flexible mode (the S31) */
int chain_pps_flex_stop(void)
{
	uint32_t ctrl_old = EMAC_PTP.pps_ctrl.val;

	EMAC_PTP.pps_ctrl.val = PPS_CTRL_PPSEN0 | (PPS_TRGT_PPS_ONLY << PPS_CTRL_TRGT_SHIFT) |
				PPS_CMD_STOP_NOW;
	if ((EMAC_PTP.pps_ctrl.val & PPS_CTRL_PPSEN0) == 0U) {
		EMAC_PTP.pps_ctrl.val = ctrl_old;
		return -ENODEV;
	}
	return 0;
}
```

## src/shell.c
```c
/*
 * SPDX-License-Identifier: GPL-3.0-or-later
 *
 * Shell: chain start|stop|peer|stat|dump|info|servo|pps.
 */
#include <ctype.h>
#include <stdlib.h>

#include <zephyr/drivers/ethernet/eth_dwmac_fast.h>
#include <zephyr/device.h>
#include <zephyr/drivers/ptp_clock.h>
#include <zephyr/net/phy.h>
#include <zephyr/net/ptp_time.h>
#include <zephyr/shell/shell.h>

#include "chain.h"

static const char *const role_name[] = {"idle", "seme", "uke"};

static int cmd_start(const struct shell *sh, size_t argc, char **argv)
{
	uint32_t us = argc > 1 ? strtoul(argv[1], NULL, 0) : 0;
	uint32_t rounds = argc > 2 ? strtoul(argv[2], NULL, 0) : 0;

	if (us != 0 && us < 100) {
		shell_error(sh, "interval_us at least 100");
		return -EINVAL;
	}
	if (rounds > 100) {
		shell_error(sh, "rounds_per_burst at most 100");
		return -EINVAL;
	}
	if (chain_start(us, rounds) != 0) {
		shell_error(sh, "no peer: chain peer <mac> first (the other board's MAC from chain info)");
		return -ENOTCONN;
	}
	shell_print(sh, "seme: interval %u us, %u rounds per burst", chain_interval_us(),
		    chain_rounds());
	return 0;
}

/* Parse aa:bb:cc:dd:ee:ff, exactly 6 bytes of 2 hex digits. */
static bool parse_mac(const char *s, uint8_t mac[6])
{
	for (int i = 0; i < 6; i++) {
		int hi, lo;

		if (!isxdigit((unsigned char)s[0]) || !isxdigit((unsigned char)s[1])) {
			return false;
		}
		hi = isdigit((unsigned char)s[0]) ? s[0] - '0' : (tolower((unsigned char)s[0]) - 'a' + 10);
		lo = isdigit((unsigned char)s[1]) ? s[1] - '0' : (tolower((unsigned char)s[1]) - 'a' + 10);
		mac[i] = (uint8_t)(hi << 4 | lo);
		s += 2;
		if (i < 5 && *s++ != ':') {
			return false;
		}
	}
	return *s == '\0';
}

/* peer [<mac> | clear] */
static int cmd_peer(const struct shell *sh, size_t argc, char **argv)
{
	uint8_t m[6];
	int ret;

	if (argc == 1) {
		if (chain_peer_get(m)) {
			shell_print(sh, "peer %02x:%02x:%02x:%02x:%02x:%02x", m[0], m[1], m[2], m[3],
				    m[4], m[5]);
		} else {
			shell_print(sh, "peer none");
		}
		return 0;
	}
	if (strcmp(argv[1], "clear") == 0) {
		ret = chain_peer_clear();
	} else if (parse_mac(argv[1], m)) {
		ret = chain_peer_set(m);
	} else {
		shell_error(sh, "peer <aa:bb:cc:dd:ee:ff> | clear");
		return -EINVAL;
	}
	if (ret != 0) {
		shell_error(sh, "chain is running: chain stop first");
		return ret;
	}
	return 0;
}

static int cmd_stop(const struct shell *sh, size_t argc, char **argv)
{
	chain_stop();
	shell_print(sh, "stopped (still answers)");
	return 0;
}

static int onoff(const struct shell *sh, const char *s, atomic_t *flag, const char *name)
{
	if (strcmp(s, "on") == 0) {
		atomic_set(flag, 1);
	} else if (strcmp(s, "off") == 0) {
		atomic_set(flag, 0);
	} else {
		shell_error(sh, "on or off");
		return -EINVAL;
	}
	shell_print(sh, "%s %s", name, s);
	return 0;
}

static int cmd_stat(const struct shell *sh, size_t argc, char **argv)
{
	return onoff(sh, argv[1], &chain_stat_on, "stat");
}

/* servo on [period_ms] [bw_hz] [clamp_ns] | off */
static int cmd_servo(const struct shell *sh, size_t argc, char **argv)
{
	if (strcmp(argv[1], "on") == 0) {
		uint32_t period_ms = argc > 2 ? strtoul(argv[2], NULL, 0) : 50;
		double bw_hz = argc > 3 ? strtod(argv[3], NULL) : 2.0;
		uint32_t clamp_ns = argc > 4 ? strtoul(argv[4], NULL, 0) : 500;

		if (period_ms < 10 || period_ms > 1000 || bw_hz < 0.01 || bw_hz > 10.0 ||
		    clamp_ns == 0) {
			shell_error(sh, "period_ms 10..1000, bw_hz 0.01..10, clamp_ns > 0");
			return -EINVAL;
		}
		chain_servo_config(period_ms, (uint32_t)(bw_hz * 1000.0 + 0.5), clamp_ns);
		atomic_set(&chain_servo_on, 1);
		shell_print(sh, "servo on (uke only): period %u ms, bandwidth %.3f Hz, clamp %u ns",
			    period_ms, bw_hz, clamp_ns);
		return 0;
	}
	return onoff(sh, argv[1], &chain_servo_on, "servo");
}

/* seq,base_sec,t1_ps,t2_ps,t3_ps,t4_ps; a servo step as a # line */
static int cmd_dump(const struct shell *sh, size_t argc, char **argv)
{
	uint32_t end = chain_log_count();
	uint32_t n = argc > 1 ? strtoul(argv[1], NULL, 0) : CONFIG_APP_CHAIN_LOG;
	uint32_t i;

	if (n > CONFIG_APP_CHAIN_LOG) {
		n = CONFIG_APP_CHAIN_LOG;
	}
	if (n > end) {
		n = end;
	}
	shell_print(sh, "# seq,base_sec,t1_ps,t2_ps,t3_ps,t4_ps (t1,t4 local, t2,t3 peer; offset = peer - local)");
	for (i = end - n; i != end; i++) {
		struct chain_xchg x;

		if (!chain_log_get(i, &x)) {
			shell_warn(sh, "# log overwritten while printing");
			break;
		}
		if (x.seq == CHAIN_LOG_STEP) {
			shell_print(sh, "# servo step %lld ps", (long long)x.t_ps[0]);
			continue;
		}
		shell_print(sh, "%u,%u,%lld,%lld,%lld,%lld", x.seq, x.base_sec,
			    (long long)x.t_ps[0], (long long)x.t_ps[1], (long long)x.t_ps[2],
			    (long long)x.t_ps[3]);
	}
	return 0;
}

static int cmd_info(const struct shell *sh, size_t argc, char **argv)
{
	const struct device *clk = DEVICE_DT_GET(DT_NODELABEL(ptp_clock));
	const struct device *phy = DEVICE_DT_GET(DT_NODELABEL(phy));
	const uint8_t *m = chain_mac();
	uint8_t pm[6];
	struct net_ptp_time t;
	struct phy_link_state ls;
	struct dwmac_rx_stats rs;
	int ret;

	shell_print(sh, "mac %02x:%02x:%02x:%02x:%02x:%02x role %s interval %u us rounds %u", m[0],
		    m[1], m[2], m[3], m[4], m[5], role_name[chain_role_get()], chain_interval_us(),
		    chain_rounds());
	if (chain_peer_get(pm)) {
		shell_print(sh, "peer %02x:%02x:%02x:%02x:%02x:%02x", pm[0], pm[1], pm[2], pm[3],
			    pm[4], pm[5]);
	} else {
		shell_print(sh, "peer none");
	}
	shell_print(sh, "ptp subsec: %s, fine ssinc %s", CHAIN_DIGITAL ? "digital (ns)" : "binary (2^-31 s)",
		    IS_ENABLED(CONFIG_PTP_CLOCK_DWC_MAC_FINE_SSINC) ? "yes" : "no");
	ret = ptp_clock_get(clk, &t);
	if (ret == 0) {
		shell_print(sh, "ptp time %llu.%09u s", (unsigned long long)t.second, t.nanosecond);
	}
	ret = phy_get_link_state(phy, &ls);
	if (ret == 0) {
		shell_print(sh, "link %s speed %s", ls.is_up ? "up" : "down",
			    PHY_LINK_IS_SPEED_1000M(ls.speed) ? "1000M" :
			    PHY_LINK_IS_SPEED_100M(ls.speed) ? "100M" :
			    PHY_LINK_IS_SPEED_10M(ls.speed) ? "10M" : "?");
	}
	dwmac_rx_stats_get(chain_eth, &rs);
	shell_print(sh, "mac rx: offered %u claimed %u missed %u fifo_ovf %u starved %u", rs.offered,
		    rs.claimed, rs.missed, rs.fifo_overflow, rs.starved);
	shell_print(sh, "tx sent %u busy %u no_peer %u fail %u stamp_missing %u", chain_cnt.tx_sent,
		    chain_cnt.tx_busy, chain_cnt.tx_no_peer, chain_cnt.tx_fail,
		    chain_cnt.tx_stamp_missing);
	shell_print(sh, "rx chain %u nostamp %u stale %u lost %u", chain_cnt.rx_chain,
		    chain_cnt.rx_nostamp, chain_cnt.rx_stale, chain_cnt.rx_lost);
	shell_print(sh, "exchanges %u rejected %u ring_overflow %u reentry %u bursts %u skipped %u chain_end %u",
		    chain_cnt.exchanges, chain_cnt.rejected, chain_cnt.ring_overflow,
		    chain_cnt.reentry, chain_cnt.bursts, chain_cnt.burst_skipped, chain_cnt.chain_end);
	shell_print(sh, "stat %s servo %s (steps %u) log %u", atomic_get(&chain_stat_on) ? "on" : "off",
		    atomic_get(&chain_servo_on) ? "on" : "off", chain_servo_steps(),
		    chain_log_count());
	return 0;
}

/* pps <n> | pps flex [width_us] [clk] | pps stop */
static int cmd_pps(const struct shell *sh, size_t argc, char **argv)
{
	int ret;

	if (strcmp(argv[1], "flex") == 0) {
		struct chain_pps_info i;
		uint32_t width_us = argc > 2 ? strtoul(argv[2], NULL, 0) : 1000;
		bool ref_clk = argc > 3 && strcmp(argv[3], "clk") == 0;

		ret = chain_pps_flex(width_us, ref_clk, &i);
		if (ret != 0) {
			shell_error(sh, "flexible PPS failed: %d", ret);
			return ret;
		}
		shell_print(sh, "pulse train from PTP second %llu: tick %u ps, interval %u ticks, "
			    "width %u ticks", (unsigned long long)i.start_sec, i.tick_ps,
			    i.interval_ticks, i.width_ticks);
		return 0;
	}
	if (strcmp(argv[1], "stop") == 0) {
		return chain_pps_flex_stop();
	}
	ret = chain_pps_set(strtoul(argv[1], NULL, 0));
	if (ret != 0) {
		shell_error(sh, "n is 0 to 15, flex [width_us] [clk], or stop");
	}
	return ret;
}

SHELL_STATIC_SUBCMD_SET_CREATE(chain_cmds,
	SHELL_CMD_ARG(start, NULL, "[interval_us] [rounds_per_burst]", cmd_start, 1, 2),
	SHELL_CMD_ARG(peer, NULL, "[<aa:bb:cc:dd:ee:ff> | clear]: unicast destination", cmd_peer, 1, 1),
	SHELL_CMD_ARG(stop, NULL, "stop the bursts", cmd_stop, 1, 0),
	SHELL_CMD_ARG(stat, NULL, "on|off: print the 1 s window", cmd_stat, 2, 0),
	SHELL_CMD_ARG(dump, NULL, "[n]: last exchanges as CSV", cmd_dump, 1, 1),
	SHELL_CMD_ARG(info, NULL, "state and counters", cmd_info, 1, 0),
	SHELL_CMD_ARG(servo, NULL, "on [period_ms] [bw_hz] [clamp_ns] | off: the uke follows the seme", cmd_servo, 2, 3),
	SHELL_CMD_ARG(pps, NULL, "<n> | flex [width_us] [clk] | stop", cmd_pps, 2, 2),
	SHELL_SUBCMD_SET_END);

SHELL_CMD_REGISTER(chain, &chain_cmds, "PTP chain", NULL);
```
